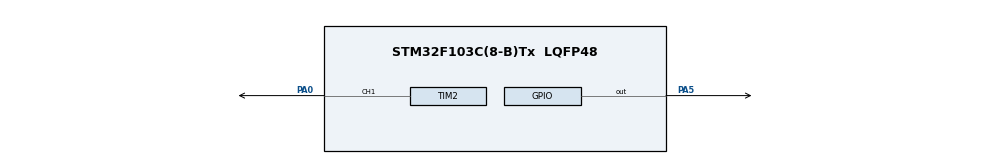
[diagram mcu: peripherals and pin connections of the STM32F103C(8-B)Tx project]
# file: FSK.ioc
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Mcu.Family=STM32F1
Mcu.Name=STM32F103C(8-B)Tx
Mcu.Package=LQFP48
NVIC.PriorityGroup=NVIC_PRIORITYGROUP_4
PA0-WKUP.Signal=S_TIM2_CH1_ETR
PA5.Signal=GPIO_Output
ProjectManager.HeapSize=0x200
ProjectManager.StackSize=0x400
ProjectManager.TargetToolchain=MDK-ARM V5.32
RCC.APB1Freq_Value=8000000
RCC.APB2Freq_Value=8000000
SH.S_TIM2_CH1_ETR.0=TIM2_CH1,PWM Generation1 CH1
TIM2.Channel-PWM\ Generation1\ CH1=TIM_CHANNEL_1
VP_SYS_VS_ND.Mode=No_Debug
board=custom

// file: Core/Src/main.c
/* USER CODE BEGIN Header */
/**
  ******************************************************************************
  * @file           : main.c
  * @brief          : Main program body
  ******************************************************************************
  * @attention
  *
  * Copyright (c) 2025 STMicroelectronics.
  * All rights reserved.
  *
  * This software is licensed under terms that can be found in the LICENSE file
  * in the root directory of this software component.
  * If no LICENSE file comes with this software, it is provided AS-IS.
  *
  ******************************************************************************
  */
/* USER CODE END Header */
#include "main.h"

TIM_HandleTypeDef htim2;

void SystemClock_Config(void);
static void MX_GPIO_Init(void);
static void MX_TIM2_Init(void);
/* USER CODE BEGIN PFP */
void Transmit_FSK(uint8_t *data, uint16_t size, uint32_t freq_0, uint32_t freq_1);
/* USER CODE END PFP */

int main(void)
{

  /* MCU Configuration--------------------------------------------------------*/

  /* Reset of all peripherals, Initializes the Flash interface and the Systick. */
  HAL_Init();

  /* Configure the system clock */
  SystemClock_Config();

  /* Initialize all configured peripherals */
  MX_GPIO_Init();
  MX_TIM2_Init();
  /* USER CODE BEGIN 2 */
	HAL_TIM_PWM_Start(&htim2, TIM_CHANNEL_1);
	uint8_t data[] = {0,1,0,1,1,0,1,0};
  /* USER CODE END 2 */

  /* Infinite loop */
  while (1)
  {
		Transmit_FSK(data,sizeof(data),1000,2000);
		HAL_Delay(500);

  }
}

void SystemClock_Config(void)
{
  RCC_OscInitTypeDef RCC_OscInitStruct = {0};
  RCC_ClkInitTypeDef RCC_ClkInitStruct = {0};

  /** Initializes the RCC Oscillators according to the specified parameters
  * in the RCC_OscInitTypeDef structure.
  */
  RCC_OscInitStruct.OscillatorType = RCC_OSCILLATORTYPE_HSI;
  RCC_OscInitStruct.HSIState = RCC_HSI_ON;
  RCC_OscInitStruct.HSICalibrationValue = RCC_HSICALIBRATION_DEFAULT;
  RCC_OscInitStruct.PLL.PLLState = RCC_PLL_NONE;
  if (HAL_RCC_OscConfig(&RCC_OscInitStruct) != HAL_OK)
  {
    Error_Handler();
  }

  /** Initializes the CPU, AHB and APB buses clocks
  */
  RCC_ClkInitStruct.ClockType = RCC_CLOCKTYPE_HCLK|RCC_CLOCKTYPE_SYSCLK
                              |RCC_CLOCKTYPE_PCLK1|RCC_CLOCKTYPE_PCLK2;
  RCC_ClkInitStruct.SYSCLKSource = RCC_SYSCLKSOURCE_HSI;
  RCC_ClkInitStruct.AHBCLKDivider = RCC_SYSCLK_DIV1;
  RCC_ClkInitStruct.APB1CLKDivider = RCC_HCLK_DIV1;
  RCC_ClkInitStruct.APB2CLKDivider = RCC_HCLK_DIV1;

  if (HAL_RCC_ClockConfig(&RCC_ClkInitStruct, FLASH_LATENCY_0) != HAL_OK)
  {
    Error_Handler();
  }
}

static void MX_TIM2_Init(void)
{

  TIM_MasterConfigTypeDef sMasterConfig = {0};
  TIM_OC_InitTypeDef sConfigOC = {0};

  htim2.Instance = TIM2;
  htim2.Init.Prescaler = 0;
  htim2.Init.CounterMode = TIM_COUNTERMODE_UP;
  htim2.Init.Period = 65535;
  htim2.Init.ClockDivision = TIM_CLOCKDIVISION_DIV1;
  htim2.Init.AutoReloadPreload = TIM_AUTORELOAD_PRELOAD_DISABLE;
  if (HAL_TIM_PWM_Init(&htim2) != HAL_OK)
  {
    Error_Handler();
  }
  sMasterConfig.MasterOutputTrigger = TIM_TRGO_RESET;
  sMasterConfig.MasterSlaveMode = TIM_MASTERSLAVEMODE_DISABLE;
  if (HAL_TIMEx_MasterConfigSynchronization(&htim2, &sMasterConfig) != HAL_OK)
  {
    Error_Handler();
  }
  sConfigOC.OCMode = TIM_OCMODE_PWM1;
  sConfigOC.Pulse = 0;
  sConfigOC.OCPolarity = TIM_OCPOLARITY_HIGH;
  sConfigOC.OCFastMode = TIM_OCFAST_DISABLE;
  if (HAL_TIM_PWM_ConfigChannel(&htim2, &sConfigOC, TIM_CHANNEL_1) != HAL_OK)
  {
    Error_Handler();
  }
  HAL_TIM_MspPostInit(&htim2);

}

static void MX_GPIO_Init(void)
{
  GPIO_InitTypeDef GPIO_InitStruct = {0};

  /* GPIO Ports Clock Enable */
  __HAL_RCC_GPIOA_CLK_ENABLE();

  /*Configure GPIO pin Output Level */
  HAL_GPIO_WritePin(GPIOA, GPIO_PIN_5, GPIO_PIN_RESET);

  /*Configure GPIO pin : PA5 */
  GPIO_InitStruct.Pin = GPIO_PIN_5;
  GPIO_InitStruct.Mode = GPIO_MODE_OUTPUT_PP;
  GPIO_InitStruct.Pull = GPIO_NOPULL;
  GPIO_InitStruct.Speed = GPIO_SPEED_FREQ_LOW;
  HAL_GPIO_Init(GPIOA, &GPIO_InitStruct);

}

void Error_Handler(void)
{
  __disable_irq();
  while (1)
  {
  }
}

/*
 * Hàm thay d?i t?n s? PWM
 * Input: freq - t?n s? mong mu?n (Hz)
 * Gi? d?nh:
 *   - S? d?ng TIM2 (32-bit timer)
 *   - PWM Mode 1 trên Channel 1
 *   - Duty cycle c? d?nh 50%
 *   - Timer clock = HAL_RCC_GetPCLK1Freq() * 2 (vì APB1 prescaler >=2)
 */
void Set_PWM_Frequency(uint32_t freq)
{
    uint32_t timer_clk = HAL_RCC_GetPCLK1Freq() * 2;  // Clock vào TIM2 (APB1 thu?ng nhân 2)
    uint32_t prescaler = 0;
    uint32_t period = 0;

    // Tìm prescaler phù h?p d? period không vu?t quá 16-bit (0xFFFF)
    for (prescaler = 0; prescaler < 0xFFFF; prescaler++)
    {
        period = timer_clk / ((prescaler + 1) * freq);

        if (period <= 0xFFFF)
        {
            break;  // Tìm du?c prescaler phù h?p
        }
    }

    // N?u không tìm du?c (t?n s? quá th?p), có th? x? lý riêng, nhung hi?m x?y ra

    // C?p nh?t thông s? cho TIM2
    __HAL_TIM_SET_PRESCALER(&htim2, prescaler);
    __HAL_TIM_SET_AUTORELOAD(&htim2, period);

    // Duty cycle 50% ? Compare = period / 2
    __HAL_TIM_SET_COMPARE(&htim2, TIM_CHANNEL_1, period / 2);

    // Kích ho?t c?p nh?t ngay l?p t?c
    HAL_TIM_GenerateEvent(&htim2, TIM_EVENTSOURCE_UPDATE);
}
/*
 * Phát tín hi?u FSK theo chu?i nh? phân
 * Bit 0 ? phát t?n s? freq_0
 * Bit 1 ? phát t?n s? freq_1
 * M?i bit kéo dài 10ms
 */
void Transmit_FSK(uint8_t *data, uint16_t size, uint32_t freq_0, uint32_t freq_1)
{
    for (uint16_t i = 0; i < size; i++)
    {
        // N?u bit = 0 ? phát t?n s? freq_0, ngu?c l?i phát freq_1
        if (data[i] == 0)
        {
            Set_PWM_Frequency(freq_0);
        }
        else
        {
            Set_PWM_Frequency(freq_1);
        }

        HAL_Delay(10);  // M?i bit kéo dài 10ms
    }
}
